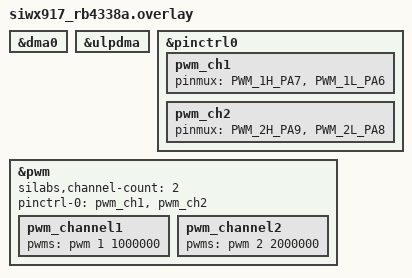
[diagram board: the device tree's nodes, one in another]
/*
 * Copyright (c) 2024 Silicon Laboratories Inc.
 *
 * SPDX-License-Identifier: Apache-2.0
 */

tst_dma0: &dma0 {
	status = "okay";
};

tst_dma1: &ulpdma {
	status = "okay";
};

&pinctrl0 {
    pwm_ch1: pwm_ch1 {
        pinmux = <PWM_1H_PA7>, <PWM_1L_PA6>;
    };
    pwm_ch2: pwm_ch2 {
        pinmux = <PWM_2H_PA9>, <PWM_2L_PA8>;
    };
};

&pwm {
	silabs,channel-count = <2>;
    	pinctrl-0 = <&pwm_ch1>, <&pwm_ch2>;
   	pinctrl-names = "default";	
    	pwm_channel1: pwm_channel1  {
    		pwms = <&pwm 1 1000000>;    // Channel 1, 1ms period (1000000 ns)
    	};
    	pwm_channel2: pwm_channel2  {
    		pwms = <&pwm 2 2000000>;    // Channel 2, 1ms period (1000000 ns)
    	};
	status = "okay";
};
